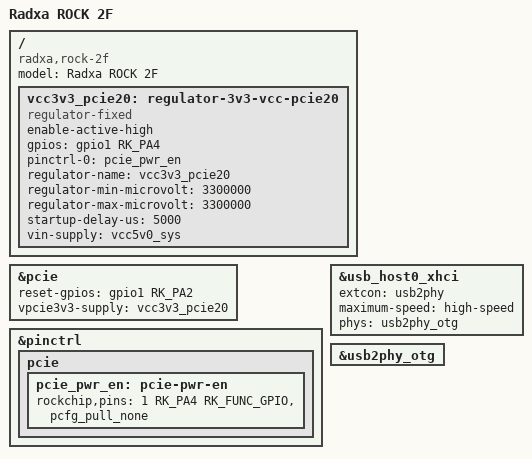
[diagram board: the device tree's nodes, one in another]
// SPDX-License-Identifier: (GPL-2.0+ OR MIT)

/dts-v1/;

#include "rk3528-rock-2.dtsi"

/ {
	model = "Radxa ROCK 2F";
	compatible = "radxa,rock-2f", "rockchip,rk3528";

	vcc3v3_pcie20: regulator-3v3-vcc-pcie20 {
		compatible = "regulator-fixed";
		enable-active-high;
		gpios = <&gpio1 RK_PA4 GPIO_ACTIVE_HIGH>;
		pinctrl-names = "default";
		pinctrl-0 = <&pcie_pwr_en>;
		regulator-name = "vcc3v3_pcie20";
		regulator-min-microvolt = <3300000>;
		regulator-max-microvolt = <3300000>;
		startup-delay-us = <5000>;
		vin-supply = <&vcc5v0_sys>;
	};
};

&pcie {
	reset-gpios = <&gpio1 RK_PA2 GPIO_ACTIVE_HIGH>;
	vpcie3v3-supply = <&vcc3v3_pcie20>;
	status = "okay";
};

&pinctrl {
	pcie {
		pcie_pwr_en: pcie-pwr-en {
			rockchip,pins = <1 RK_PA4 RK_FUNC_GPIO &pcfg_pull_none>;
		};
	};
};

&usb_host0_xhci {
	extcon = <&usb2phy>;
	maximum-speed = "high-speed";
	phys = <&usb2phy_otg>;
	phy-names = "usb2-phy";
	status = "okay";
};

&usb2phy_otg {
	status = "okay";
};
